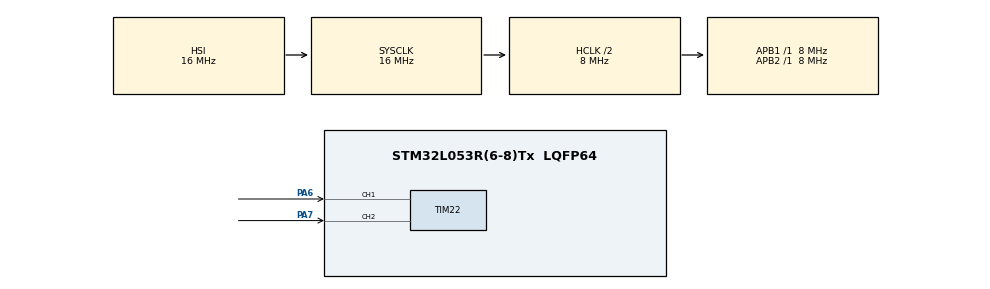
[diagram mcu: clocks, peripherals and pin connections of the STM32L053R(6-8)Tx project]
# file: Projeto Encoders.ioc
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Mcu.Family=STM32L0
Mcu.Name=STM32L053R(6-8)Tx
Mcu.Package=LQFP64
PA6.Signal=S_TIM22_CH1
PA7.Signal=S_TIM22_CH2
ProjectManager.HeapSize=0x200
ProjectManager.StackSize=0x400
ProjectManager.TargetToolchain=STM32CubeIDE
RCC.AHBCLKDivider=RCC_SYSCLK_DIV2
RCC.AHBFreq_Value=8000000
RCC.APB1Freq_Value=8000000
RCC.APB1TimFreq_Value=8000000
RCC.APB2Freq_Value=8000000
RCC.APB2TimFreq_Value=8000000
RCC.HCLKFreq_Value=8000000
RCC.HSE_VALUE=8000000
RCC.HSI16_VALUE=16000000
RCC.HSI48_VALUE=48000000
RCC.HSI_VALUE=16000000
RCC.MSI_VALUE=2097000
RCC.SYSCLKFreq_VALUE=16000000
RCC.SYSCLKSource=RCC_SYSCLKSOURCE_HSI
RCC.VCOOutputFreq_Value=48000000
SH.S_TIM22_CH1.0=TIM22_CH1,Encoder_Interface
SH.S_TIM22_CH2.0=TIM22_CH2,Encoder_Interface
TIM22.EncoderMode=TIM_ENCODERMODE_TI12
TIM22.IC1Filter=10
TIM22.IC1Polarity=TIM_ICPOLARITY_FALLING
TIM22.IC2Filter=10
TIM22.IC2Polarity=TIM_ICPOLARITY_FALLING
board=NUCLEO-L053R8

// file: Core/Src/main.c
/* USER CODE BEGIN Header */
/**
  ******************************************************************************
  * @file           : main.c
  * @brief          : Main program body
  ******************************************************************************
  * @attention
  *
  * Copyright (c) 2025 STMicroelectronics.
  * All rights reserved.
  *
  * This software is licensed under terms that can be found in the LICENSE file
  * in the root directory of this software component.
  * If no LICENSE file comes with this software, it is provided AS-IS.
  *
  ******************************************************************************
  */
/* USER CODE END Header */
#include "main.h"

TIM_HandleTypeDef htim22;

/* USER CODE BEGIN PV */
uint32_t Count = 0, Verify = 0;
/* USER CODE END PV */

void SystemClock_Config(void);
static void MX_GPIO_Init(void);
static void MX_TIM22_Init(void);
/* USER CODE BEGIN PFP */
void Encoder_Init(void);
void TIM2_IRQHandler(void);
int32_t Encoder_GetCount(void);
/* USER CODE END PFP */

int main(void)
{

  /* MCU Configuration--------------------------------------------------------*/

  /* Reset of all peripherals, Initializes the Flash interface and the Systick. */
  HAL_Init();

  /* Configure the system clock */
  SystemClock_Config();

  /* Initialize all configured peripherals */
  MX_GPIO_Init();
  MX_TIM22_Init();
  /* USER CODE BEGIN 2 */
  Encoder_Init();

  /* USER CODE END 2 */

  /* Infinite loop */
  /* USER CODE BEGIN WHILE */
  while (1)
  {
	  Count  = Encoder_GetCount();
	  Verify = TIM2_IRQHandler();
    /* USER CODE END WHILE */

  }
}

void SystemClock_Config(void)
{
  RCC_OscInitTypeDef RCC_OscInitStruct = {0};
  RCC_ClkInitTypeDef RCC_ClkInitStruct = {0};

  /** Configure the main internal regulator output voltage
  */
  __HAL_PWR_VOLTAGESCALING_CONFIG(PWR_REGULATOR_VOLTAGE_SCALE1);

  /** Initializes the RCC Oscillators according to the specified parameters
  * in the RCC_OscInitTypeDef structure.
  */
  RCC_OscInitStruct.OscillatorType = RCC_OSCILLATORTYPE_HSI;
  RCC_OscInitStruct.HSIState = RCC_HSI_ON;
  RCC_OscInitStruct.HSICalibrationValue = RCC_HSICALIBRATION_DEFAULT;
  RCC_OscInitStruct.PLL.PLLState = RCC_PLL_NONE;
  if (HAL_RCC_OscConfig(&RCC_OscInitStruct) != HAL_OK)
  {
    Error_Handler();
  }

  /** Initializes the CPU, AHB and APB buses clocks
  */
  RCC_ClkInitStruct.ClockType = RCC_CLOCKTYPE_HCLK|RCC_CLOCKTYPE_SYSCLK
                              |RCC_CLOCKTYPE_PCLK1|RCC_CLOCKTYPE_PCLK2;
  RCC_ClkInitStruct.SYSCLKSource = RCC_SYSCLKSOURCE_HSI;
  RCC_ClkInitStruct.AHBCLKDivider = RCC_SYSCLK_DIV2;
  RCC_ClkInitStruct.APB1CLKDivider = RCC_HCLK_DIV1;
  RCC_ClkInitStruct.APB2CLKDivider = RCC_HCLK_DIV1;

  if (HAL_RCC_ClockConfig(&RCC_ClkInitStruct, FLASH_LATENCY_0) != HAL_OK)
  {
    Error_Handler();
  }
}

static void MX_TIM22_Init(void)
{

  TIM_Encoder_InitTypeDef sConfig = {0};
  TIM_MasterConfigTypeDef sMasterConfig = {0};

  htim22.Instance = TIM22;
  htim22.Init.Prescaler = 0;
  htim22.Init.CounterMode = TIM_COUNTERMODE_UP;
  htim22.Init.Period = 65535;
  htim22.Init.ClockDivision = TIM_CLOCKDIVISION_DIV1;
  htim22.Init.AutoReloadPreload = TIM_AUTORELOAD_PRELOAD_DISABLE;
  sConfig.EncoderMode = TIM_ENCODERMODE_TI12;
  sConfig.IC1Polarity = TIM_ICPOLARITY_FALLING;
  sConfig.IC1Selection = TIM_ICSELECTION_DIRECTTI;
  sConfig.IC1Prescaler = TIM_ICPSC_DIV1;
  sConfig.IC1Filter = 10;
  sConfig.IC2Polarity = TIM_ICPOLARITY_FALLING;
  sConfig.IC2Selection = TIM_ICSELECTION_DIRECTTI;
  sConfig.IC2Prescaler = TIM_ICPSC_DIV1;
  sConfig.IC2Filter = 10;
  if (HAL_TIM_Encoder_Init(&htim22, &sConfig) != HAL_OK)
  {
    Error_Handler();
  }
  sMasterConfig.MasterOutputTrigger = TIM_TRGO_RESET;
  sMasterConfig.MasterSlaveMode = TIM_MASTERSLAVEMODE_DISABLE;
  if (HAL_TIMEx_MasterConfigSynchronization(&htim22, &sMasterConfig) != HAL_OK)
  {
    Error_Handler();
  }

}

static void MX_GPIO_Init(void)
{

  /* GPIO Ports Clock Enable */
  __HAL_RCC_GPIOA_CLK_ENABLE();

}

/* USER CODE BEGIN 4 */
void Encoder_Init(void)
{
    // Habilitar o clock do TIM2 (supondo que estamos usando o TIM2)
    __HAL_RCC_TIM2_CLK_ENABLE();

    // Estrutura de configuração do timer
    TIM_HandleTypeDef htim22;

    htim22.Instance = TIM22; // Usando o TIM2
    htim22.Init.Prescaler = 0; // Nenhum prescaler adicional
    htim22.Init.CounterMode = TIM_COUNTERMODE_UP; // Contador crescente
    htim22.Init.Period = 0xFFFF; // Valor máximo de contagem
    htim22.Init.ClockDivision = TIM_CLOCKDIVISION_DIV1; // Divisor do clock
    htim22.Init.AutoReloadPreload = TIM_AUTORELOAD_PRELOAD_DISABLE; // Desabilitar preload
}

// Função para ler a contagem do encoder
int32_t Encoder_GetCount(void)
{
    TIM_HandleTypeDef htim22;
    return __HAL_TIM_GET_COUNTER(&htim22);  // Retorna a contagem atual do contador do encoder
}

// Função de interrupção - chamada quando ocorre uma mudança no valor do encoder
void TIM2_IRQHandler(void)
{
    if (__HAL_TIM_GET_IT_SOURCE(&htim22, TIM_IT_UPDATE) != RESET)
    {
        __HAL_TIM_CLEAR_IT(&htim22, TIM_IT_UPDATE); // Limpar a interrupção
        Count = Encoder_GetCount(); // Atualiza a contagem do encoder
    }
}
/* USER CODE END 4 */

void Error_Handler(void)
{
  __disable_irq();
  while (1)
  {
  }
}
